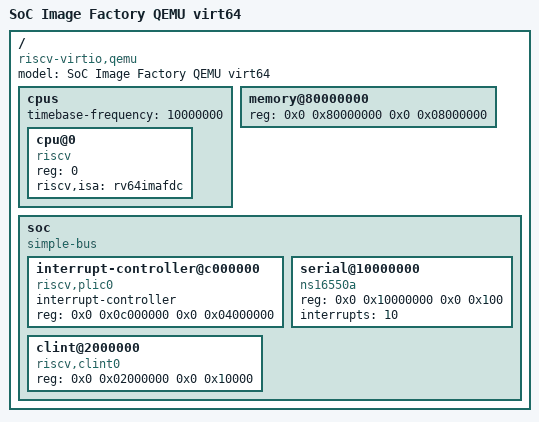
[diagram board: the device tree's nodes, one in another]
/dts-v1/;

/ {
    model = "SoC Image Factory QEMU virt64";
    compatible = "riscv-virtio,qemu";
    #address-cells = <2>;
    #size-cells = <2>;

    cpus {
        #address-cells = <1>;
        #size-cells = <0>;
        timebase-frequency = <10000000>;
        cpu@0 {
            device_type = "cpu";
            compatible = "riscv";
            reg = <0>;
            riscv,isa = "rv64imafdc";
        };
    };

    memory@80000000 {
        device_type = "memory";
        reg = <0x0 0x80000000 0x0 0x08000000>;
    };

    soc {
        compatible = "simple-bus";
        #address-cells = <2>;
        #size-cells = <2>;
        ranges;

        interrupt-controller@c000000 {
            compatible = "riscv,plic0";
            interrupt-controller;
            #interrupt-cells = <1>;
            reg = <0x0 0x0c000000 0x0 0x04000000>;
        };

        serial@10000000 {
            compatible = "ns16550a";
            reg = <0x0 0x10000000 0x0 0x100>;
            interrupts = <10>;
        };

        clint@2000000 {
            compatible = "riscv,clint0";
            reg = <0x0 0x02000000 0x0 0x10000>;
        };
    };
};
